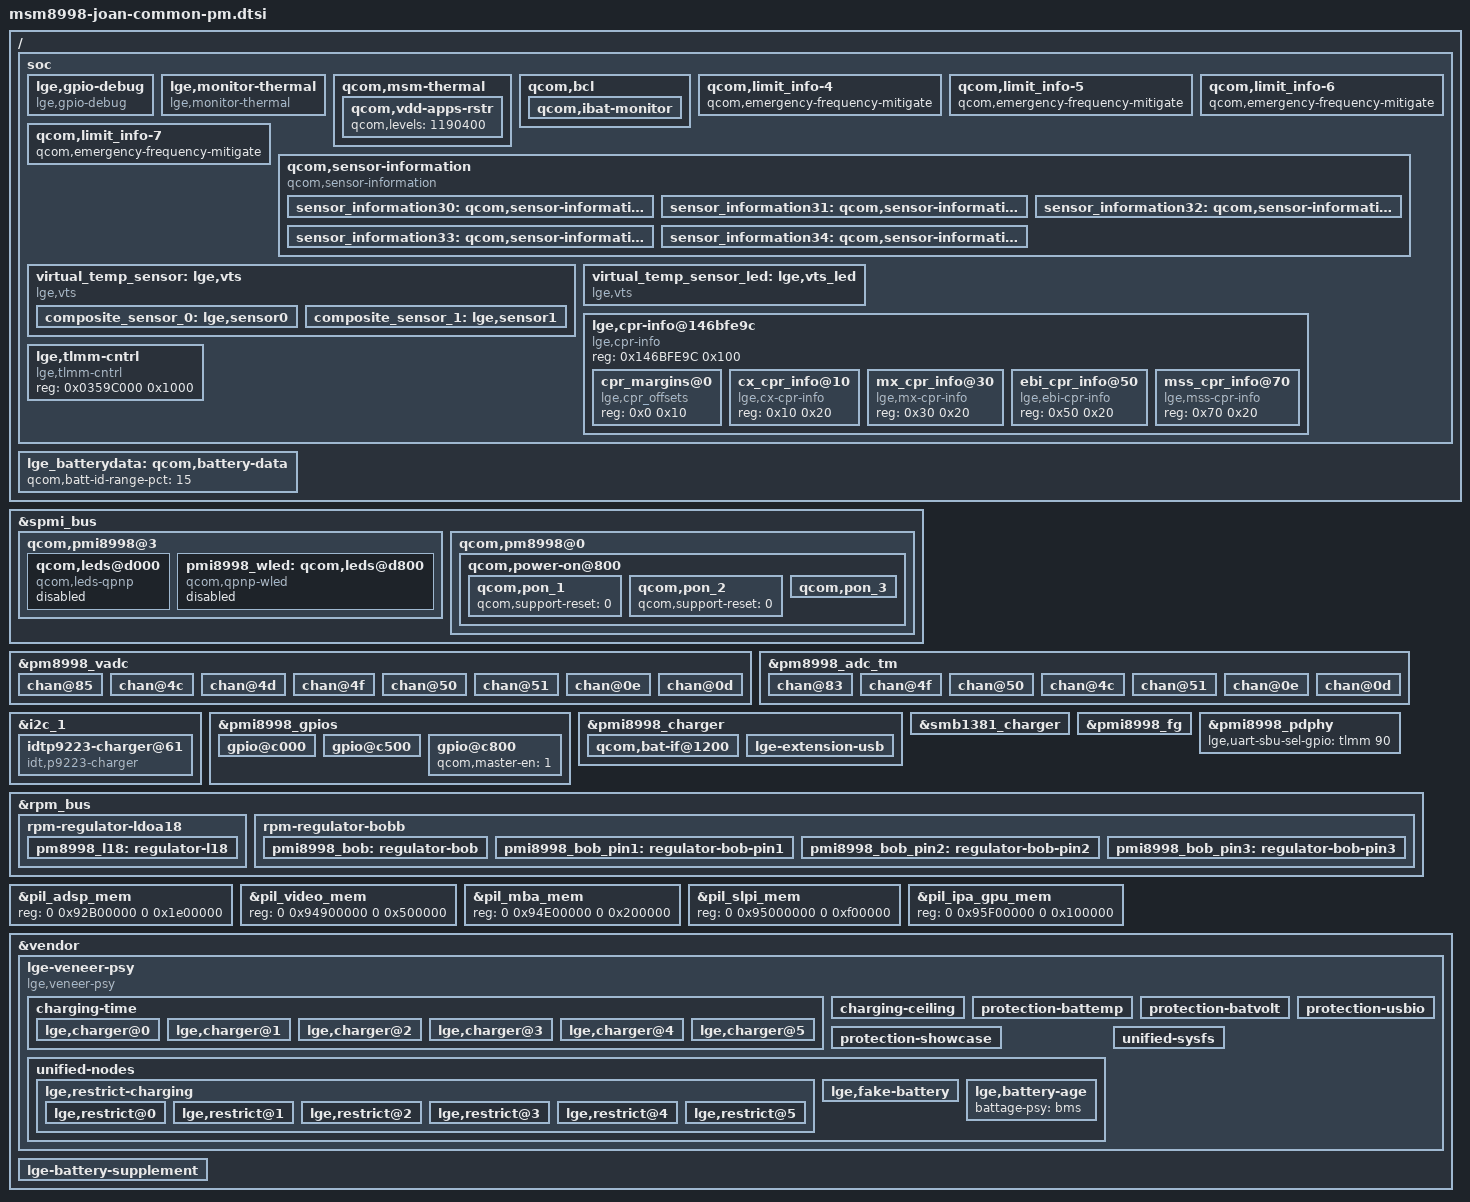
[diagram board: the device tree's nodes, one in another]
/* Copyright (c) 2014, The Linux Foundation. All rights reserved.
 *
 * This program is free software; you can redistribute it and/or modify
 * it under the terms of the GNU General Public License version 2 and
 * only version 2 as published by the Free Software Foundation.
 *
 * This program is distributed in the hope that it will be useful,
 * but WITHOUT ANY WARRANTY; without even the implied warranty of
 * MERCHANTABILITY or FITNESS FOR A PARTICULAR PURPOSE.  See the
 * GNU General Public License for more details.
 */

/ {
	soc {
		lge,gpio-debug {
			compatible = "lge,gpio-debug";
			reg = <0x03500000 0x900000>;
			reg-names = "tlmm-base";
			lge,n-msm-gpio = <0x96>;  /* MSM8996 GPIO 0 to 149 */
		};

		lge,monitor-thermal {
			compatible = "lge,monitor-thermal";
			status = "ok";
			lge,hot-poll-time = <10000>;
			lge,hot-crit-temp = <48>;
			lge,poll-time = <30000>;
			qcom,monitor-thermal-vadc = <&pm8998_vadc>;
		};

		qcom,msm-thermal {
			qcom,disable-gfx-phase-ctrl;
			qcom,disable-psm;
			qcom,disable-ocr;
			qcom,disable-cx-phase-ctrl;
			qcom,disable-vdd-mx;
			qcom,disable-vdd-rstr;
			/* mitigate gold cluster freq to 1.536Ghz */
			qcom,freq-mitigation-temp = <95>;
			qcom,freq-mitigation-temp-hysteresis = <10>;
			qcom,freq-mitigation-value = <1536000>;
			qcom,vdd-apps-rstr {
				qcom,levels = <1190400>;
			};

		};

		qcom,bcl {
			/delete-property/ qcom,bcl-soc-hotplug-list;
			qcom,ibat-monitor {
				qcom,soc-low-threshold = <0>;
				qcom,mitigation-freq-khz = <1190400>;
			};
		};

		qcom,limit_info-4 {
			qcom,emergency-frequency-mitigate;
		};

		qcom,limit_info-5 {
			qcom,emergency-frequency-mitigate;
		};

		qcom,limit_info-6 {
			qcom,emergency-frequency-mitigate;
		};

		qcom,limit_info-7 {
			qcom,emergency-frequency-mitigate;
		};

		qcom,sensor-information {
			compatible = "qcom,sensor-information";

			sensor_information30: qcom,sensor-information-30 {
				qcom,sensor-type = "adc";
				qcom,sensor-name = "xo_therm";
			};

			sensor_information31: qcom,sensor-information-31 {
				qcom,sensor-type = "adc";
				qcom,sensor-name = "bd_therm_2";
			};

			sensor_information32: qcom,sensor-information-32 {
				qcom,sensor-type = "adc";
				qcom,sensor-name = "vts";
				qcom,scaling-factor = <10>;
			};

			sensor_information33: qcom,sensor-information-33 {
				qcom,sensor-type = "adc";
				qcom,sensor-name = "led_sensor";
				qcom,scaling-factor = <10>;
			};

			sensor_information34: qcom,sensor-information-34 {
				qcom,sensor-type = "adc";
				qcom,sensor-name = "battery";
				qcom,scaling-factor = <1000>;
			};
		};

		/* TODO : tune, vts, 0.37*XO + 0.48*Bd2 + 3.83 */
		virtual_temp_sensor: lge,vts {
			compatible = "lge,vts";
			lge,index = <101>;
			qcom,vts-vadc = <&pm8998_vadc>;
			lge,scaling-factor = <10>;
			lge,constant-milli = <3830>;

			composite_sensor_0: lge,sensor0 {
				label = "xo_therm";
				channel = <0x4c>;
				weight-milli = <370>;
			};

			composite_sensor_1: lge,sensor1 {
				label = "bd_therm_2";
				channel = <0x51>;
				weight-milli = <480>;
			};
		};

		virtual_temp_sensor_led: lge,vts_led {
			compatible = "lge,vts";
			lge,name = "led_sensor";
			lge,index = <102>;
			qcom,vts-vadc = <&pm8998_vadc>;
			lge,scaling-factor= <1>;
		};

		lge,cpr-info@146bfe9c {
			compatible = "lge,cpr-info";
			reg = <0x146BFE9C 0x100>;
			ranges = <0x0 0x146BFE9C 0x100>;
			#address-cells = <1>;
			#size-cells = <1>;

			cpr_margins@0 {
				compatible = "lge,cpr_offsets";
				reg = <0x0 0x10>;
			};

			cx_cpr_info@10{
				compatible = "lge,cx-cpr-info";
				reg = <0x10 0x20>;
			};
			mx_cpr_info@30{
				compatible = "lge,mx-cpr-info";
				reg = <0x30 0x20>;
			};
			ebi_cpr_info@50{
				compatible = "lge,ebi-cpr-info";
				reg = <0x50 0x20>;
			};
			mss_cpr_info@70{
				compatible = "lge,mss-cpr-info";
				reg = <0x70 0x20>;
			};
		};

                lge,tlmm-cntrl{
                        compatible = "lge,tlmm-cntrl";
                        reg = <0x0359C000  0x1000>;
                        reg-names = "ufs-clk-base";
                };

	};
};

&spmi_bus {
	qcom,pmi8998@3 {
		qcom,leds@d000 {
			compatible = "qcom,leds-qpnp";
			reg = <0xd000 0x100>;
			label = "rgb";
			status = "disabled";
		};
		pmi8998_wled: qcom,leds@d800 {
			compatible = "qcom,qpnp-wled";
			status = "disabled";
		};
	};
};

&pm8998_vadc {
	lge,gpio-sbu-oe = <&tlmm 16 0>;
	lge,gpio-edge-sel = <&tlmm 42 0>;
	chan@85 {
		label = "vcoin";
		reg = <0x85>;
		qcom,decimation = <2>;
		qcom,pre-div-channel-scaling = <1>;
		qcom,calibration-type = "absolute";
		qcom,scale-function = <0>;
		qcom,hw-settle-time = <0>;
		qcom,fast-avg-setup = <0>;
	};

	chan@4c {
		label = "xo_therm";
		reg = <0x4c>;
		qcom,decimation = <2>;
		qcom,pre-div-channel-scaling = <0>;
		qcom,calibration-type = "ratiometric";
		qcom,scale-function = <4>;
		qcom,hw-settle-time = <2>;
		qcom,fast-avg-setup = <0>;
	};

	chan@4d {
		label = "pcb_rev";
		reg = <0x4d>;
		qcom,decimation = <0>;
		qcom,pre-div-channel-scaling = <0>;
		qcom,calibration-type = "ratiometric";
		qcom,scale-function = <0>;
		qcom,hw-settle-time = <1>;
		qcom,fast-avg-setup = <0>;
	};

	chan@4f {
		label = "pa_therm0";
		reg = <0x4f>;
		qcom,decimation = <2>;
		qcom,pre-div-channel-scaling = <0>;
		qcom,calibration-type = "ratiometric";
		qcom,scale-function = <2>;
		qcom,hw-settle-time = <2>;
		qcom,fast-avg-setup = <0>;
	};

	chan@50 {
		label = "pa_therm1";
		reg = <0x50>;
		qcom,decimation = <2>;
		qcom,pre-div-channel-scaling = <0>;
		qcom,calibration-type = "ratiometric";
		qcom,scale-function = <2>;
		qcom,hw-settle-time = <2>;
		qcom,fast-avg-setup = <0>;
	};

	chan@51 {
		label = "bd_therm_2";
		reg = <0x51>;
		qcom,decimation = <2>;
		qcom,pre-div-channel-scaling = <0>;
		qcom,calibration-type = "ratiometric";
		qcom,scale-function = <2>;
		qcom,hw-settle-time = <2>;
		qcom,fast-avg-setup = <0>;
	};

	chan@0e {
		label = "usb_id_lv";
		reg = <0x0e>;
		qcom,decimation = <0>;
		qcom,pre-div-channel-scaling = <0>;
		qcom,calibration-type = "ratiometric";
		qcom,scale-function = <0>;
		qcom,hw-settle-time = <5>;
		qcom,fast-avg-setup = <0>;
	};

	chan@0d {
		label = "usb_edge";
		reg = <0x4d>;
		qcom,decimation = <0>;
		qcom,pre-div-channel-scaling = <0>;
		qcom,calibration-type = "ratiometric";
		qcom,scale-function = <0>;
		qcom,hw-settle-time = <5>;
		qcom,fast-avg-setup = <0>;
	};
};

&pm8998_adc_tm {
	chan@83 {
		label = "vph_pwr";
		reg = <0x83>;
		qcom,pre-div-channel-scaling = <1>;
		qcom,calibration-type = "absolute";
		qcom,scale-function = <0>;
		qcom,hw-settle-time = <0>;
		qcom,btm-channel-number = <0x60>;
	};

	chan@4f {
		label = "pa_therm0";
		reg = <0x4f>;
		qcom,decimation = <2>;
		qcom,pre-div-channel-scaling = <0>;
		qcom,calibration-type = "ratiometric";
		qcom,scale-function = <2>;
		qcom,hw-settle-time = <2>;
		qcom,fast-avg-setup = <0>;
		qcom,btm-channel-number = <0x68>;
		qcom,thermal-node;
	};

	chan@50 {
		label = "pa_therm1";
		reg = <0x50>;
		qcom,decimation = <2>;
		qcom,pre-div-channel-scaling = <0>;
		qcom,calibration-type = "ratiometric";
		qcom,scale-function = <2>;
		qcom,hw-settle-time = <2>;
		qcom,fast-avg-setup = <0>;
		qcom,btm-channel-number = <0x70>;
		qcom,thermal-node;
	};

	chan@4c {
		label = "xo_therm";
		reg = <0x4c>;
		qcom,pre-div-channel-scaling = <0>;
		qcom,calibration-type = "ratiometric";
		qcom,scale-function = <4>;
		qcom,hw-settle-time = <2>;
		qcom,btm-channel-number = <0x78>;
		qcom,thermal-node;
	};

	chan@51 {
		label = "bd_therm_2";
		reg = <0x51>;
		qcom,pre-div-channel-scaling = <0>;
		qcom,calibration-type = "ratiometric";
		qcom,scale-function = <2>;
		qcom,hw-settle-time = <2>;
		qcom,btm-channel-number = <0x80>;
		qcom,thermal-node;
	};

	chan@0e {
		label = "usb_id_lv";
		reg = <0x0e>;
		qcom,btm-channel-number = <0x88>;
		qcom,decimation = <0>;
		qcom,pre-div-channel-scaling = <0>;
		qcom,calibration-type = "ratiometric";
		qcom,scale-function = <0>;
		qcom,hw-settle-time = <5>;
		qcom,fast-avg-setup = <0>;
	};

	chan@0d {
		label = "usb_edge";
		reg = <0x4d>;
		qcom,btm-channel-number = <0x90>;
		qcom,decimation = <0>;
		qcom,pre-div-channel-scaling = <0>;
		qcom,calibration-type = "ratiometric";
		qcom,scale-function = <0>;
		qcom,hw-settle-time = <5>;
		qcom,fast-avg-setup = <0>;
	};
};

&i2c_1 { /* BLSP1 QUP1 */
	status = "okay";

	idtp9223-charger@61 {               /* Slave driver and slave Address */
		compatible ="idt,p9223-charger";    /* Manufacture, model */
		reg = <0x61>;               /* Slave Address */
		interrupt-parent = <&tlmm>;         /* GPIO handler */
		interrupts = <24 0x0>;         /* GPIO # will be converted to gpio_activated # */

		idt,gpio-interrupt = <&tlmm 24 0>;
		idt,gpio-disabling = <&pmi8998_gpios 9 0>;
		idt,configure-overheat = <600>;
		idt,configure-sysfs = <1>;

		status = "ok";
	};
};

&pmi8998_gpios {
	gpio@c000 {
		qcom,mode = <1>;
		qcom,output-type = <0>;
		qcom,invert = <1>;
		qcom,vin-sel = <0>;
		qcom,out-strength = <1>;
		qcom,src-sel = <0>;
		qcom,master-en = <1>;
		status = "okay";
	};
	gpio@c500 {
		status = "okay";
                qcom,mode = <1>;
		qcom,pull = <5>;
		qcom,vin-sel = <0>;
		qcom,src-sel = <2>;
		qcom,out-strength = <1>;
		qcom,master-en = <1>;
	};
	gpio@c800 {
		qcom,master-en = <1>;		/* Enable GPIO */
		status = "okay";
	};
};

&pmi8998_charger {
	qcom,usb-icl-ua = <1800000>;
	qcom,fcc-max-ua = <3300000>;
	qcom,otg-cl-ua = <1250000>;
	qcom,dc-icl-ua = <900000>;
	qcom,dc-psy-type = "Wireless";
	qcom,float-option = <2>;
	qcom,batt-life-cycle-set = <0 200 300 400>;
	qcom,batt-life-cycle-fcc-ma = <3300000 3000000 2900000 2700000>;
	qcom,auto-recharge-soc;
	qcom,usbid-vadc = <&pm8998_vadc>;
	lge,maximum-icl-ua = <3000000>;

	bvc-vddcx-supply = <&pm8998_s1_level>;
	bvc-vddcx-minlv = <RPM_SMD_REGULATOR_LEVEL_MIN_SVS>;
	bvc-vddcx-maxlv = <RPM_SMD_REGULATOR_LEVEL_TURBO>;

	io-channels = <&pmi8998_rradc 8>,
		      <&pmi8998_rradc 10>,
		      <&pmi8998_rradc 11>,
		      <&pmi8998_rradc 3>,
		      <&pmi8998_rradc 4>,
		      <&pmi8998_rradc 5>,
		      <&pmi8998_rradc 6>,
		      <&pmi8998_rradc 2>,
		      <&pmi8998_rradc 12>,
		      <&pmi8998_rradc 13>;

	io-channel-names = "charger_temp",
			   "charger_temp_max",
			   "charger_temp_hot_max",
			   "usbin_i",
			   "usbin_v",
			   "dcin_i",
			   "dcin_v",
			   "skin_temp",
			   "skin_temp_max",
			   "skin_temp_hot_max";

	qcom,bat-if@1200 {
		reg = <0x1200 0x100>;
		interrupts = <0x2 0x12 0x0 IRQ_TYPE_NONE>,
			     <0x2 0x12 0x1 IRQ_TYPE_NONE>,
			     <0x2 0x12 0x2 IRQ_TYPE_NONE>,
			     <0x2 0x12 0x3 IRQ_TYPE_NONE>,
			     <0x2 0x12 0x4 IRQ_TYPE_NONE>,
			     <0x2 0x12 0x5 IRQ_TYPE_NONE>,
			     <0x2 0x12 0x6 IRQ_TYPE_NONE>;

		interrupt-names = "bat-temp",
				  "bat-ocp",
				  "bat-ov",
				  "bat-low",
				  "bat-therm-or-id-missing",
				  "bat-terminal-missing",
				  "bat-qi-pma-on";
	};

	lge-extension-usb {
		lge,usbid-adc-channel = <0x0e>;		// ADC channel# (refer to pm8998_vadc)
		lge,usbid-adc-range = <30>;		// ADC margin (pct unit)
		lge,usbid-pullup-mvol = <1800>;		// Pull-up voltage
		lge,renewal-usbid-pullup-mvol = <1000>;		// Pull-up voltage for renewal
		lge,usbid-pullup-kohm = <200>;		// Pull-up resistance

		lge,feature-moisture-charging = <0>;
	};
};

/{
	lge_batterydata: qcom,battery-data {
		qcom,batt-id-range-pct = <15>;
		#include "../../LGE_BLT34_LGC_3300mAh.dtsi"
	};
};

&smb1381_charger {
	lge,disable-connector-temp;
	lge,smb-bat-en-gpio = <&pmi8998_gpios 1 0>;
};

&pmi8998_fg {
	qcom,battery-data = <&lge_batterydata>;
	lge,batt_id = <100000>;
	qcom,lge_batt_profile;
	lge,fg-esr-rt-filter-switch-temp = <150 200 250>;
	lge,fg-esr-rt-filter-duration = <2400000 1800000 900000>;
	qcom,fg-esr-tight-rt-filter-micro-pct = <498000>;
	qcom,fg-esr-broad-rt-filter-micro-pct = <498000>;
	qcom,fg-esr-tight-lt-filter-micro-pct = <30000>;
	qcom,fg-esr-broad-lt-filter-micro-pct = <30000>;
	qcom,fg-auto-recharge-soc;
	qcom,fg-recharge-soc-thr = <97>;
	qcom,fg-cutoff-voltage = <3200>;
	qcom,fg-cutoff-current = <200>;
	qcom,cycle-counter-en;
	qcom,cl-max-temp = <420>;
	qcom,cl-max-increment = <0>;
	qcom,fg-batt-life-cycle-set = <0 200 300 400>;
	qcom,fg-batt-life-cycle-offset = <0 2 7 11>;
	qcom,fg-batt-life-cycle-vfloat = <4400000 4390000 4370000 4350000>;
};

/*
&pmi8998_qnovo {
	lge,enable-qni-debounce;
	lge,qni-debounce-time = <900000>;
	lge,qni-debounce-soc = <229>;
	lge,qni-debounce-esr = <150000>;
	lge,qni-debounce-voltage = <100000>;
	lge,qni-debounce-therm = <150>;

	lge,enable-qni-probation;
	lge,qni-step-min-fcc = <700000>;
	lge,qni-probation-min-fv = <4400000>;
	lge,qni-probation-max-fcc = <950000>;
	lge,qni-probation-enter-fcc = <1000000>;
};
*/

&pmi8998_pdphy {
	lge,uart-sbu-sel-gpio = <&tlmm 90 0 >;
};

&spmi_bus {
	qcom,pm8998@0 {
		qcom,power-on@800 {
			qcom,s3-debounce = <32>;
			qcom,s3-src = "kpdpwr-and-resin";

			qcom,pon_1 {  /* KPD_PWR_N */
				status = "ok";
				qcom,support-reset = <0>;
			};

			qcom,pon_2 {  /* RESIN_N */
				status = "ok";
				qcom,support-reset = <0>;
			};
			qcom,pon_3 {  /* KPD_PWR_N AND RESIN_N */
				status = "ok";
				qcom,support-reset = <1>;
				qcom,s1-timer = <6720>;
				qcom,s2-timer = <2000>;
				qcom,s2-type = <PON_POWER_OFF_DVDD_HARD_RESET>;
			};
		};
	};
};

&rpm_bus {
	rpm-regulator-ldoa18 {
		status = "okay";
		pm8998_l18: regulator-l18 {
			regulator-min-microvolt = <2704000>;
			regulator-max-microvolt = <2704000>;
			qcom,init-voltage       = <2704000>;
			qcom,vdd-voltage-level = <2704000 2704000>;
			status = "okay";
		};
	};

	rpm-regulator-bobb {
		status = "okay";
		pmi8998_bob: regulator-bob {
			qcom,pwm-threshold-current = <2000000>;
			qcom,init-bob-mode = <2>;
			status = "okay";
		};
		pmi8998_bob_pin1: regulator-bob-pin1 {
			qcom,pwm-threshold-current = <2000000>;
			qcom,init-bob-mode = <2>;
			status = "okay";
		};
		pmi8998_bob_pin2: regulator-bob-pin2 {
			qcom,pwm-threshold-current = <2000000>;
			qcom,init-bob-mode = <2>;
			status = "okay";
		};
		pmi8998_bob_pin3: regulator-bob-pin3 {
			qcom,pwm-threshold-current = <2000000>;
			qcom,init-bob-mode = <2>;
			status = "okay";
		};
	};
};

&pil_adsp_mem {
	reg = <0 0x92B00000 0 0x1e00000>;
};

&pil_video_mem {
	reg = <0 0x94900000 0 0x500000>;
};

&pil_mba_mem {
	reg = <0 0x94E00000 0 0x200000>;
};

&pil_slpi_mem {
	reg = <0 0x95000000 0 0xf00000>;
};

&pil_ipa_gpu_mem {
	reg = <0 0x95F00000 0 0x100000>;
};

&vendor {
	lge-veneer-psy {
		compatible = "lge,veneer-psy";
		status = "ok";

		charging-time {
			#address-cells = <1>;
			#size-cells = <0>;

			lge,overstatement-enable = <0>;
			lge,overstatement-weight = <2>;
			lge,overstatement-base = <100>;

			lge,maxcharging-mw-chargerlogo = <15000>;
			lge,maxcharging-mw-normal = <13000>;

			lge,charger@0 {		//  power-off fast charger: 9V * 1.6A or 5V * 3A = 15W
				charger-power = <15000>;
				charger-profile = <
					17  17  17  17  17  17  17  17  17  17  17  17  17  17  17  17
					17  17  17  17  17  17  17  17  17  17  17  17  17  17  17  17
					17  17  17  17  17  17  17  17  17  17  17  17  17  17  17  17
					17  17  17  17  17  17  17  17  17  17  17  17  17  17  17  17
					17  17  17  17  17  17  17  17  17  17  17  17  17  17  17  17
					17  17  17  17  17  17  17  17  17  17  17  17  17  17  17  17
					17  17  17  17  17  17  17  17  17  17  17  17  17  17  17  17
					17  17  17  17  17  17  17  17  17  17  17  17  17  17  17  17
					17  17  17  17  17  17  17  17  17  17  17  17  17  17  17  17
					17  17  17  17  17  17  17  17  17  17  17  17  17  17  17  17
					17  17  17  17  17  17  17  17  17  17  17  17  17  17  17  17
					17  17  17  17  17  19  19  19  19  19  19  19  19  19  19  19
					19  22  22  22  22  22  22  22  22  22  22  22  22  26  26  26
					26  26  26  26  32  32  32  32  32  32  32  32  32  32  40  40
					40  40  40  40  52  52  52  52  52  52  65  65  65  65  65  65
					70  75  80  90 100 105 105 105 105 105 105 105 105 105 105 105
				>;
			};
			lge,charger@1 {		//  power-on fast charger: 2.6A * 4.0V / 80% = 13W
				charger-power = <13000>;
				charger-profile = <
					20  20  20  20  20  20  20  20  20  20  20  20  20  20  20  20
					20  20  20  20  20  20  20  20  20  20  20  20  20  20  20  20
					20  20  20  20  20  20  20  20  20  20  20  20  20  20  20  20
					20  20  20  20  20  20  20  20  20  20  20  20  20  20  20  20
					20  20  20  20  20  20  20  20  20  20  20  20  20  20  20  20
					20  20  20  20  20  20  20  20  20  20  20  20  20  20  20  20
					20  20  20  20  20  20  20  20  20  20  20  20  20  20  20  20
					20  20  20  20  20  20  20  20  20  20  20  20  20  20  20  20
					20  20  20  20  20  20  20  20  20  20  20  20  20  20  20  20
					20  20  20  20  20  20  20  20  20  20  20  20  20  20  20  20
					20  20  20  20  20  20  20  20  20  20  20  20  20  20  20  20
					20  20  20  20  20  20  20  20  20  20  20  20  20  20  20  20
					20  22  22  22  22  22  22  22  22  22  22  22  22  26  26  26
					26  26  26  26  32  32  32  32  32  32  32  32  32  32  40  40
					40  43  43  44  45  52  52  52  52  52  65  65  65  65  65  65
					70  75  80  90 100 105 105 105 105 105 105 105 105 105 105 105
				>;
			};
			lge,charger@2 {		//  dcp: 1.8A * 5V = 9W
				charger-power = <9000>;
				charger-profile = <
					31  31  31  31  31  31  31  31  31  31  31  31  31  31  31  31
					31  31  31  31  31  31  31  31  31  31  31  31  31  31  31  31
					31  31  31  31  31  31  31  31  31  31  31  31  31  31  31  31
					31  31  31  31  31  31  31  31  31  31  31  31  31  31  31  31
					31  31  31  31  31  31  31  31  31  31  31  31  31  31  31  31
					31  31  31  31  31  31  31  31  31  31  31  31  31  31  31  31
					31  31  31  31  31  31  31  31  31  31  31  31  31  31  31  31
					31  31  31  31  31  31  31  31  31  31  31  31  31  31  31  31
					31  31  31  31  31  31  31  31  31  31  31  31  31  31  31  31
					31  31  31  31  31  31  31  31  31  31  31  31  31  31  31  31
					31  31  31  31  31  31  31  31  31  31  31  31  31  31  31  31
					31  31  31  31  31  31  31  31  31  31  31  31  31  31  31  31
					31  31  31  31  31  31  31  31  31  31  31  31  31  31  31  31
					31  31  31  31  34  34  34  34  34  34  34  34  34  34  42  42
					42  42  42  42  55  55  55  55  55  55  69  69  69  69  69  69
					70  75  80  90 100 105 105 105 105 105 105 105 105 105 105 105
				>;
			};
			lge,charger@3 {		// EPP wireless charger: 9000mV * 900mA = 8.1W
				charger-power = <8100>;
				charger-profile = <
					36  36  36  36  36  36  36  36  36  36  36  36  37  37  37  37
					37  37  37  37  37  37  37  37  37  37  38  38  38  38  38  38
					38  38  38  38  38  38  38  38  39  39  39  39  39  39  39  39
					39  39  39  39  40  40  40  40  40  40  40  40  40  40  40  40
					41  41  41  41  41  41  41  41  41  41  41  41  42  42  42  42
					42  42  42  42  42  42  42  43  43  43  43  43  43  43  43  43
					43  44  44  44  44  44  44  44  44  44  44  45  45  45  45  45
					45  45  45  45  46  46  46  46  46  46  46  46  46  47  47  47
					47  47  47  47  47  47  48  48  48  48  48  48  48  48  49  49
					49  49  49  49  49  49  50  50  50  50  50  50  50  50  51  51
					51  51  51  51  51  52  52  52  52  52  52  52  53  53  53  53
					53  53  53  54  54  54  54  54  54  54  55  55  55  55  55  55
					56  56  56  56  56  56  57  57  57  57  57  57  58  58  58  58
					58  58  59  59  59  59  59  60  60  60  60  60  61  61  61  61
					61  61  62  62  62  62  60  60  60  60  60  60  60  60  60  60
					70  75  80  90 100 105 105 105 105 105 105 105 105 105 105 105
				>;
			};
			lge,charger@4 {		// BPP wireless charger: 5000mV * 900mA = 4.5W
				charger-power = <4500>;
				charger-profile = <
					55  55  55  55  55  55  55  55  55  55  55  56  56  56  56  56
					56  56  56  56  56  56  56  56  56  56  56  56  56  56  56  56
					56  56  56  56  56  56  56  56  56  57  57  57  57  57  57  57
					57  57  57  57  57  57  57  57  57  57  57  57  57  57  57  57
					57  57  57  57  57  57  57  58  58  58  58  58  58  58  58  58
					58  58  58  58  58  58  58  58  58  58  58  58  58  58  58  58
					58  58  58  59  59  59  59  59  59  59  59  59  59  59  59  59
					59  59  59  59  59  59  59  59  59  59  59  59  59  59  59  60
					60  60  60  60  60  60  60  60  60  60  60  60  60  60  60  60
					60  60  60  60  60  60  60  60  60  61  61  61  61  61  61  61
					61  61  61  61  61  61  61  61  61  61  61  61  61  61  61  61
					61  61  61  62  62  62  62  62  62  62  62  62  62  62  62  62
					62  62  62  62  62  62  62  62  62  62  62  63  63  63  63  63
					63  63  63  63  63  63  63  63  63  63  63  63  60  60  60  60
					60  60  60  60  60  60  60  60  60  60  60  65  65  65  65  65
					70  75  80  90 100 105 105 105 105 105 105 105 105 105 105 105
				>;
			};
			lge,charger@5 {		// SDP: 5000mV * 500mA = 2.5W
				charger-power = <2500>;
				charger-profile = <
					98  98  98  98  98  98  98  98  98  98  98  98  98  98  98  98
					98  98  98  98  98  98  98  98  98  98  98  98  98  98  98  98
					98  98  98  98  98  98  98  98  98  98  98  98  98  98  98  98
					98  98  98  98  98  98  98  98  98  98  98  98  98  98  98  98
					98  98  98  98  98  98  98  98  98  98  98  98  98  98  98  98
					98  98  98  98  98  98  98  98  98  98  98  98  98  98  98  98
					98  98  98  98  98  98  98  98  98  98  98  98  98  98  98  98
					98  98  98  98  98  98  98  98  98  98  98  98  98  98  98  98
					98  98  98  98  98  98  98  98  98  98  98  98  98  98  98  98
					98  98  98  98  98  98  98  98  98  98  98  98  98  98  98  98
					98  98  98  98  98  98  98  98  98  98  98  98  98  98  98  98
					98  98  98  98  98  98  98  98  98  98  98  98  98  98  98  98
					98  98  98  98  98  98  98  98  98  98  98  98  98  98  98  98
					98  98  98  98  98  98  98  98  98  98  98  98  98  98  98  98
					98  98  98  98  98  98  98  98  98  98  98  98  98  98  98  98
					98  98  98  98  98 110 110 110 110 110 110 110 110 110 110 110
				>;
			};

		};

		charging-ceiling {
		/*	               iusb ibat  idc  : 0 means UNCEILING */
			lge,unknown = < 450  450  450>;
			lge,float   = < 500  500    0>;
			lge,none    = <   0    0    0>;

			lge,dcp     = <1800    0    0>;
			lge,10k     = <3000    0    0>;
			lge,22k     = <1500    0    0>;
			lge,qc2     = <1800    0    0>;
			lge,qc3     = <1800    0    0>;

			lge,usb2    = < 500    0    0>;
			lge,usb3    = < 900    0    0>;
			lge,cdp     = <1500 1500    0>;
			lge,pd      = <   0    0    0>;

			lge,56k     = <1500  500    0>;
			lge,130k    = <1500  500    0>;
			lge,910k    = <1500  500    0>;

			lge,w5w     = <   0    0  900>;
			lge,w9w     = <   0    0  900>;
		};

		protection-battemp {
			lge,threshold-degc-upto-cool = <30>;
			lge,threshold-degc-upto-good = <120>;
			lge,threshold-degc-upto-warm = <450>;
			lge,threshold-degc-upto-hot = <550>;
			lge,threshold-degc-downto-warm = <520>;
			lge,threshold-degc-downto-good = <430>;
			lge,threshold-degc-downto-cool = <100>;
			lge,threshold-degc-downto-cold = <0>;

			lge,period-ms-emergency	= <10000>;
			lge,period-ms-warning	= <30000>;
			lge,period-ms-normal	= <60000>;

		// parameters for warning status cool and warm
			lge,cool-mv-alert	= <4000>;
			lge,cool-ma-alert	= <500>;	// fixed 500 mA
			lge,cool-ma-pct		= <30>;		// means 0.3C rate

			lge,warm-mv-float	= <4000>;
			lge,warm-ma-pct		= <50>;		// means 0.5C rate

		// parameters for battery protection at chilly status
			lge,chilly-status-support;
			lge,chilly-degc-lowerbound = <0>;
			lge,chilly-degc-upperbound = <200>;
			lge,chilly-mv-alert	   = <4000>;
			lge,chilly-ma-alert	   = <630>;
			lge,chilly-ma-pct	   = <50>; 	// means 0.5C rate under batvol 4V
		};

		protection-batvolt {
			lge,threshold-vbat-limit = <4250>;
			lge,threshold-vbat-clear = <4200>;
			lge,threshold-ibat-pct = <70>;	// means 0.7C rate

			lge,step-ibat-ma = <100>;
			lge,step-poll-ms = <5000>;
		};

		protection-showcase {
			lge,soc-range-vzw     = <30 35>;
			lge,soc-range-default = <45 50>;
		};

		protection-usbio {

		};

		unified-nodes {
			lge,feature-charging-parallel = <1>;
			lge,feature-charging-highspeed = <1>;

			lge,restrict-charging {
				// restrict-values 0 means UNCEILING

				lge,restrict@0 {
					restrict-name = "LCD";
					restrict-type = "ibat";
					restrict-commands = "ON", "OFF";
					restrict-values = <1000      0>;
				};
				lge,restrict@1 {
					restrict-name = "CALL";
					restrict-type = "ibat";
					restrict-commands = "ON", "OFF";
					restrict-values = < 500      0>;
				};
				lge,restrict@2 {
					restrict-name = "UHDREC";
					restrict-type = "ibat";
					restrict-commands = "ON", "OFF";
					restrict-values = < 500      0>;
				};
				lge,restrict@3 {
					restrict-name = "WFD";
					restrict-type = "ibat";
					restrict-commands = "ON", "OFF";
					restrict-values = < 500      0>;
				};
				lge,restrict@4 {
					restrict-name = "TDMB";
					restrict-type = "ibat";
					restrict-commands = "MODE1", "MODE2", "OFF";
					restrict-values = <    500      300      0>;
				};
				lge,restrict@5 {
					restrict-name = "LCD";
					restrict-type = "idc";
					restrict-commands = "ON", "OFF";
					restrict-values = < 700      0>;
				};
			};

			lge,fake-battery {
				fakebatt-psy = "bms";		// What 'psy' does implement(or support) the fake battery?
				fakebatt-temperature = <400>;
				fakebatt-mvoltage = <4000>;
				fakebatt-capacity = <80>;
			};

			lge,battery-age {
				battage-psy = "bms";		// What 'psy' does implement(or support) the battery age?
			};
		};

		unified-sysfs {
			lge,symlink-map =
			/* group , user_node, kernel node */
			/* Charger */
			"charger",                     "ac_online", "NULL",
			"charger",                    "usb_online", "/sys/class/power_supply/usb/online",	/* TODO */
			"charger",                       "present", "/sys/class/power_supply/usb/present",
			"charger",                    "wlc_online", "/sys/class/power_supply/dc-wireless/online",
			"charger",                          "type", "/sys/class/power_supply/usb/real_type",
			"charger",                      "time_out", "/sys/class/power_supply/battery/safety_timer_enabled",
			"charger",              "charging_enabled", "/sys/devices/platform/lge-unified-nodes/charging_enable",
			"charger",                  "ibat_current", "/sys/class/power_supply/battery/current_now",
			"charger",                  "ichg_current", "/sys/class/power_supply/usb/current_max",
			"charger",                  "iusb_control", "NULL",
			"charger",            "thermal_mitigation", "/sys/devices/platform/lge-unified-nodes/thermald_ibat",
			"charger",        "wlc_thermal_mitigation", "/sys/class/power_supply/dc/current_max",
			"charger",       "usb_parallel_chg_status", "NULL",
			"charger", "usb_parallel_charging_enabled", "/sys/class/power_supply/parallel/charging_enabled",
			"charger", "factory_parallel_charger_test", "/sys/devices/platform/lge-unified-nodes/support_fastpl",
			"charger",            "moisture_detection", "/sys/class/power_supply/battery/moisture_detection",
			"charger",           "restricted_charging", "/sys/devices/platform/lge-unified-nodes/charging_restriction",
			"charger",              "ibat_max_current", "/sys/class/power_supply/battery/constant_charge_current_max",
			"charger",                       "chgstep", "/sys/devices/platform/lge-unified-nodes/charging_step",
			"charger",               "connection_type", "/sys/class/power_supply/dc-wireless/connection_type",
			"charger",                       "fastchg", "/sys/devices/platform/lge-unified-nodes/charger_highspeed",
			"charger",         "input_current_settled", "/sys/class/power_supply/usb/input_current_settled",
			"charger",            "store_demo_enabled", "NULL",
			"charger",     "wireless_charging_enabled", "/sys/class/power_supply/wireless/charging_enabled",
			"charger",                 "input_suspend", "/sys/class/power_supply/battery/input_suspend",
			"charger",                  "incompatible", "/sys/devices/platform/lge-unified-nodes/charger_incompatible",
			"charger",                    "hvdcp_fake", "/sys/devices/platform/lge-unified-nodes/fake_hvdcp",
			"charger",               "usb_current_max", "/sys/devices/platform/lge-unified-nodes/fake_sdpmax",
			"charger",               "fastchg_support", "/sys/devices/platform/lge-unified-nodes/support_fastchg",
			"charger",                    "usbid_type", "/sys/class/power_supply/usb/resistance_id",
			/* ADC/MPP */
			"adc",              "thermal", "/sys/class/thermal/",
			"adc",             "xo_therm", "/sys/class/hwmon/hwmon1/device/xo_therm",
			"adc",           "batt_therm", "/sys/class/power_supply/battery/temp",
			"adc",              "batt_id", "/sys/devices/platform/lge-unified-nodes/battery_valid",
			"adc",            "pa_therm0", "/sys/class/hwmon/hwmon1/device/pa_therm0",
			"adc",            "pa_therm1", "/sys/class/hwmon/hwmon1/device/pa_therm1",
			"adc",           "quiet_therm","/sys/class/hwmon/hwmon1/device/bd_therm_2",
			"adc",               "usb_in", "/sys/class/power_supply/usb/voltage_now",
			"adc",                "vcoin", "/sys/class/hwmon/hwmon1/device/vcoin",
			"adc",              "vph_pwr", "/sys/class/hwmon/hwmon1/device/vph_pwr",
			"adc",               "usb_id", "/sys/devices/platform/lge-unified-nodes/charger_usbid",
			"adc",             "usb_edge", "/sys/class/hwmon/hwmon1/device/usb_edge",
			"adc",                 "pmic", "/sys/class/thermal/thermal_zone27/temp",
			"adc",                  "vts", "/sys/class/thermal/thermal_zone34/temp",
			/* Battery */
			"battery",         "capacity", "/sys/class/power_supply/battery/capacity",
			"battery",           "health", "/sys/class/power_supply/battery/health",
			"battery",          "present", "/sys/class/power_supply/battery/present",
			"battery",      "pseudo_batt", "/sys/devices/platform/lge-unified-nodes/fake_battery",
			"battery",           "status", "/sys/class/power_supply/battery/status",
			"battery",       "status_raw", "/sys/class/power_supply/battery/status_raw",
			"battery",             "temp", "/sys/class/power_supply/battery/temp",
			"battery",    "valid_batt_id", "/sys/devices/platform/lge-unified-nodes/battery_valid",
			"battery",      "voltage_now", "/sys/class/power_supply/battery/voltage_now",
			"battery",          "vzw_chg", "/sys/devices/platform/lge-unified-nodes/charger_verbose",
			"battery",     "raw_capacity", "/sys/class/power_supply/bms/capacity_raw",
			"battery",        "condition", "/sys/devices/platform/lge-unified-nodes/battery_condition",
			"battery",      "battery_age", "/sys/devices/platform/lge-unified-nodes/battery_age",
			"battery","battery_age_level", "/sys/devices/platform/lge-unified-nodes/battery_age",
			"battery",            "cycle", "/sys/devices/platform/lge-unified-nodes/battery_cycle",
			"battery",     "battery_type", "/sys/class/power_supply/bms/battery_type",
			"battery",      "charge_full", "/sys/class/power_supply/bms/charge_full",
			"battery",   "charge_now_raw", "/sys/class/power_supply/bms/charge_now_raw",
			"battery", "time_to_full_now", "/sys/class/power_supply/battery/time_to_full_now",
			/* LCD Backlight */
			"lcd",           "brightness", "/sys/class/leds/lcd-backlight/brightness",
			"lcd",       "max_brightness", "/sys/class/leds/lcd-backlight/max_brightness",
			"lcd_ex",        "brightness", "NULL",
			"lcd_ex",    "max_brightness", "NULL",
			/* KEY LED */
			"key_led",   "red_brightness", "/sys/class/leds/red/brightness",
			"key_led", "green_brightness", "/sys/class/leds/green/brightness",
			"key_led",  "blue_brightness", "/sys/class/leds/blue/brightness",
			"key_led",  "setting",         "/sys/class/lg_rgb_led/use_patterns/setting",
			/* CPU */
			"cpu",       "cpu_idle_modes", "/sys/module/lpm_levels/system/",
			/* GPU */
			"gpu",                 "busy", "/sys/class/kgsl/kgsl-3d0/gpubusy",
			"gpu",               "gpuclk", "/sys/class/kgsl/kgsl-3d0/gpuclk",
			/* PLATFORM */
			"platform",       "speed_bin", "NULL",
			"platform",         "pvs_bin", "NULL",
			"platform",     "power_state", "/sys/power/autosleep",
			"platform",   "poweron_alarm", "/sys/module/qpnp_rtc/parameters/poweron_alarm",
			"platform",         "pcb_rev", "/sys/class/hwmon/hwmon1/device/pcb_rev",
			"platform",       "smpl_boot", "/sys/module/lge_smpl_count/parameters/smpl_boot",
			/* testmode */
			"testmode",            "temp", "/sys/class/power_supply/battery/temp",
			"testmode",     "voltage_now", "/sys/class/power_supply/battery/voltage_now",
			"testmode",          "usb_id", "/sys/devices/platform/lge-unified-nodes/charger_usbid",
			"testmode",         "batt_id", "/sys/devices/platform/lge-unified-nodes/battery_valid",
			"testmode",         "fuelval", "/sys/class/power_supply/battery/capacity",
			"testmode",        "xo_therm", "/sys/class/hwmon/hwmon1/device/xo_therm",
			"testmode",          "charge", "/sys/class/power_supply/battery/battery_charging_enabled",
			"testmode",          "chcomp", "/sys/devices/platform/lge-unified-nodes/charging_completed",
			"testmode",           "usbin", "/sys/class/power_supply/usb/voltage_now",
			"testmode",       "pa_therm0", "/sys/class/hwmon/hwmon1/device/pa_therm0",
			"testmode",       "pa_therm1", "/sys/class/hwmon/hwmon1/device/pa_therm1",
			"testmode",       "bd_therm2", "/sys/class/hwmon/hwmon1/device/bd_therm_2",
			"testmode",           "vcoin", "/sys/class/hwmon/hwmon1/device/vcoin",
			"testmode",         "vph_pwr", "/sys/class/hwmon/hwmon1/device/vph_pwr",
			"testmode",     "current_now", "/sys/class/power_supply/battery/current_now",
			"testmode",     "current_max", "/sys/class/power_supply/usb/current_max",
			"testmode",         "pcb_rev", "/sys/class/hwmon/hwmon1/device/pcb_rev",
			"testmode",      "chgmodeoff", "/sys/class/power_supply/battery/input_suspend",
			"testmode",         "fuelrst", "/sys/class/power_supply/battery/present",
			"testmode",        "rtc_time", "/dev/rtc0",
			"testmode",           "pmrst", "NULL",
			"testmode",        "battexit", "/sys/class/power_supply/battery/present",
			"testmode",  "hardreset_mode", "NULL",
			/* ps feature*/
			"psfeature",     "vfps_ratio", "/sys/class/graphics/fb0/mdp/vfps_ratio",
			"psfeature",           "vfps", "/sys/class/graphics/fb0/mdp/vfps",
			"psfeature",      "vfps_fcnt", "/sys/class/graphics/fb0/mdp/vfps_fcnt",
			"psfeature",  "triton_policy", "/sys/devices/system/cpu/triton/cur_policy",
			"psfeature",   "cancun_is_cm", "NULL";
		};
	};

	lge-battery-supplement {
		capacity-mah-min = <3150>;
		capacity-raw-full = <247>;

		default-battery-name = "LGE_BLT34_LGC_3300mAh";
		default-battery-kohm = <200>;

		/* format : (temp index) (temp delta) */
		tempcomp-offset = <
			(-300) (-50)
			(-200) ( -9)
			(-190) ( -5)
			(-180)    0
			(-170)    5
			(-160)   10
			(-150)   12
			(-100)   27
			(-50)    35
			0        37
			50       25
			100      22
			150      14
			200       4
			250    ( -7)
			300    (-19)
			350    (-30)
			400    (-36)
			450    (-44)
			500    (-64)
			550    (-36)
			600    (-31)
			700    (-10)
			800    (-10)
			900    (-10)
		>;

		tempcomp-offset-wlc-enable;
		tempcomp-offset-wlc-rise-filter-enable;
		tempcomp-offset-wlc-rise-filter-trigger = <430>;
		tempcomp-offset-wlc-lcdoff = <
			(-300) (-50)
			(-200) ( -9)
			(-190) ( -5)
			(-180)    0
			(-170)    5
			(-160)   10
			(-150)   12
			(-100)   27
			(-50)    35
			0        37
			50       25
			100      22
			150      14
			200       4
			250    ( -7)
			300    (-19)
			350    (-18)
			400    (-17)
			450    (-21)
			500    (-23)
			550    (-15)
			600    (-10)
			700    (-10)
			800    (-10)
			900    (-10)
		>;

		tempcomp-offset-wlc-lcdon = <
			(-300) (-50)
			(-200) ( -9)
			(-190) ( -5)
			(-180)    0
			(-170)    5
			(-160)   10
			(-150)   12
			(-100)   27
			(-50)    35
			0        37
			50       25
			100      22
			150      14
			200       4
			250    ( -7)
			300    (-19)
			350    (-30)
			400    (-36)
			450    (-44)
			500    (-64)
			550    (-36)
			600    (-31)
			700    (-10)
			800    (-10)
			900    (-10)
		>;

		tempcomp-qnovo-charging;
		lg-monotonic-soc-enable;

		tempcomp-icoeff = <100>;
	};
};
